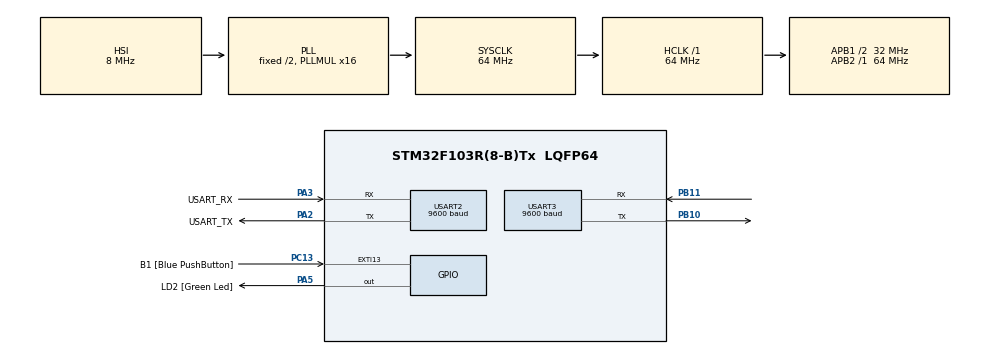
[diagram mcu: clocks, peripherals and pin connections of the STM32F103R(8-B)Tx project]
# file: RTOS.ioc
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Mcu.Family=STM32F1
PC15-OSC32_OUT.Mode=LSE-External-Oscillator
PA2.GPIO_PuPd=GPIO_NOPULL
FREERTOS.Queues01=myQueue01,16,uint16_t,0,Dynamic,NULL,NULL
FREERTOS.Tasks01=defaultTask,24,128,StartDefaultTask,Default,NULL,Dynamic,NULL,NULL;myTask02,24,128,StartTask02,Default,NULL,Dynamic,NULL,NULL;myTask03,24,128,StartTask03,Default,NULL,Dynamic,NULL,NULL
FREERTOS.BinarySemaphores01=myBinarySem01,Dynamic,NULL
PD1-OSC_OUT.Mode=HSE-External-Clock-Source
PB10.Mode=Asynchronous
PA14.GPIO_Label=TCK
PA3.GPIO_PuPd=GPIO_NOPULL
PA2.GPIO_Speed=GPIO_SPEED_FREQ_LOW
PC13-TAMPER-RTC.Signal=GPXTI13
PD0-OSC_IN.Signal=RCC_OSC_IN
FREERTOS.CountingSemaphores01=Semaphore_Cnt,5,Dynamic,NULL
RCC.APB1CLKDivider=RCC_HCLK_DIV2
PC14-OSC32_IN.Signal=RCC_OSC32_IN
PB11.Signal=USART3_RX
PA3.GPIO_Speed=GPIO_SPEED_FREQ_LOW
USART2.BaudRate=9600
RCC.SYSCLKSource=RCC_SYSCLKSOURCE_PLLCLK
ProjectManager.StackSize=0x400
VP_FREERTOS_VS_CMSIS_V2.Mode=CMSIS_V2
PD1-OSC_OUT.Signal=RCC_OSC_OUT
PA3.Mode=Asynchronous
PA13.Signal=SYS_JTMS-SWDIO
VP_SYS_VS_tim3.Mode=TIM3
USART3.BaudRate=9600
PB11.Mode=Asynchronous
ProjectManager.TargetToolchain=STM32CubeIDE
PA3.GPIO_Mode=GPIO_MODE_AF_PP
RCC.HCLKFreq_Value=64000000
RCC.APB2TimFreq_Value=64000000
RCC.USBFreq_Value=64000000
PC15-OSC32_OUT.Signal=RCC_OSC32_OUT
RCC.AHBFreq_Value=64000000
PD0-OSC_IN.Mode=HSE-External-Clock-Source
PB10.Signal=USART3_TX
NVIC.EXTI15_10_IRQn=true\:5\:0\:false\:false\:true\:true\:true\:true
PA5.Signal=GPIO_Output
PB3.Mode=Trace_Asynchronous_SW
board=NUCLEO-F103RB
RCC.RTCClockSelection=RCC_RTCCLKSOURCE_LSE
PC13-TAMPER-RTC.GPIO_Label=B1 [Blue PushButton]
RCC.PLLMUL=RCC_PLL_MUL16
NVIC.TIM3_IRQn=true\:0\:0\:false\:false\:true\:false\:false\:true
RCC.APB2Freq_Value=64000000
PC14-OSC32_IN.Mode=LSE-External-Oscillator
PA5.GPIO_ModeDefaultOutputPP=GPIO_MODE_OUTPUT_PP
PA14.Mode=Trace_Asynchronous_SW
PA5.GPIO_PuPd=GPIO_NOPULL
PA13.Mode=Trace_Asynchronous_SW
Mcu.Name=STM32F103R(8-B)Tx
PA13.GPIO_Label=TMS
PA2.Signal=USART2_TX
PB3.Signal=SYS_JTDO-TRACESWO
RCC.SYSCLKFreq_VALUE=64000000
Mcu.Package=LQFP64
NVIC.TimeBase=TIM3_IRQn
PA5.GPIO_Label=LD2 [Green Led]
USART2.VirtualMode=VM_ASYNC
USART3.VirtualMode=VM_ASYNC
PC13-TAMPER-RTC.GPIO_PuPd=GPIO_NOPULL
PA2.GPIO_Label=USART_TX
NVIC.TimeBaseIP=TIM3
PA14.Signal=SYS_JTCK-SWCLK
ProjectManager.HeapSize=0x200
FREERTOS.Timers01=myTimer01,Callback01,osTimerPeriodic,Default,NULL,Dynamic,NULL
FREERTOS.Mutexes01=Mutex1,Dynamic,NULL
PA5.GPIO_Speed=GPIO_SPEED_FREQ_LOW
NVIC.PriorityGroup=NVIC_PRIORITYGROUP_4
RCC.APB1TimFreq_Value=64000000
PA2.Mode=Asynchronous
RCC.APB1Freq_Value=32000000
PA3.GPIO_Label=USART_RX
PA3.Signal=USART2_RX
PA2.GPIO_Mode=GPIO_MODE_AF_PP
PB3.GPIO_Label=SWO

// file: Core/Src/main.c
/* USER CODE BEGIN Header */
/**
  ******************************************************************************
  * @file           : main.c
  * @brief          : Main program body
  ******************************************************************************
  * @attention
  *
  * <h2><center>&copy; Copyright (c) 2021 STMicroelectronics.
  * All rights reserved.</center></h2>
  *
  * This software component is licensed by ST under BSD 3-Clause license,
  * the "License"; You may not use this file except in compliance with the
  * License. You may obtain a copy of the License at:
  *                        opensource.org/licenses/BSD-3-Clause
  *
  ******************************************************************************
  */
/* USER CODE END Header */
#include "main.h"
#include "cmsis_os.h"
#include "usart.h"
#include "gpio.h"

/* USER CODE BEGIN Includes */
#include <stdio.h>
/* USER CODE END Includes */

void SystemClock_Config(void);
void MX_FREERTOS_Init(void);

int main(void)
{

  /* MCU Configuration--------------------------------------------------------*/

  /* Reset of all peripherals, Initializes the Flash interface and the Systick. */
  HAL_Init();

  /* Configure the system clock */
  SystemClock_Config();

  /* Initialize all configured peripherals */
  MX_GPIO_Init();
  MX_USART2_UART_Init();
  MX_USART3_UART_Init();
  /* USER CODE BEGIN 2 */
  //printf("RTOS CMSIS V2 Test\r\n");
  /* USER CODE END 2 */

  /* Init scheduler */
  osKernelInitialize();  /* Call init function for freertos objects (in freertos.c) */
  MX_FREERTOS_Init();
  /* Start scheduler */
  osKernelStart();

  /* We should never get here as control is now taken by the scheduler */
  /* Infinite loop */
  while (1)
  {

  }
}

void SystemClock_Config(void)
{
  RCC_OscInitTypeDef RCC_OscInitStruct = {0};
  RCC_ClkInitTypeDef RCC_ClkInitStruct = {0};

  /** Initializes the RCC Oscillators according to the specified parameters
  * in the RCC_OscInitTypeDef structure.
  */
  RCC_OscInitStruct.OscillatorType = RCC_OSCILLATORTYPE_HSI;
  RCC_OscInitStruct.HSIState = RCC_HSI_ON;
  RCC_OscInitStruct.HSICalibrationValue = RCC_HSICALIBRATION_DEFAULT;
  RCC_OscInitStruct.PLL.PLLState = RCC_PLL_ON;
  RCC_OscInitStruct.PLL.PLLSource = RCC_PLLSOURCE_HSI_DIV2;
  RCC_OscInitStruct.PLL.PLLMUL = RCC_PLL_MUL16;
  if (HAL_RCC_OscConfig(&RCC_OscInitStruct) != HAL_OK)
  {
    Error_Handler();
  }
  /** Initializes the CPU, AHB and APB buses clocks
  */
  RCC_ClkInitStruct.ClockType = RCC_CLOCKTYPE_HCLK|RCC_CLOCKTYPE_SYSCLK
                              |RCC_CLOCKTYPE_PCLK1|RCC_CLOCKTYPE_PCLK2;
  RCC_ClkInitStruct.SYSCLKSource = RCC_SYSCLKSOURCE_PLLCLK;
  RCC_ClkInitStruct.AHBCLKDivider = RCC_SYSCLK_DIV1;
  RCC_ClkInitStruct.APB1CLKDivider = RCC_HCLK_DIV2;
  RCC_ClkInitStruct.APB2CLKDivider = RCC_HCLK_DIV1;

  if (HAL_RCC_ClockConfig(&RCC_ClkInitStruct, FLASH_LATENCY_2) != HAL_OK)
  {
    Error_Handler();
  }
}

 /**
  * @brief  Period elapsed callback in non blocking mode
  * @note   This function is called  when TIM3 interrupt took place, inside
  * HAL_TIM_IRQHandler(). It makes a direct call to HAL_IncTick() to increment
  * a global variable "uwTick" used as application time base.
  * @param  htim : TIM handle
  * @retval None
  */
void HAL_TIM_PeriodElapsedCallback(TIM_HandleTypeDef *htim)
{
  if (htim->Instance == TIM3) {
    HAL_IncTick();
  }
}

void Error_Handler(void)
{
  __disable_irq();
  while (1)
  {
  }
}

/************************ (C) COPYRIGHT STMicroelectronics *****END OF FILE****/

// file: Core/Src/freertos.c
/* USER CODE BEGIN Header */
/**
  ******************************************************************************
  * File Name          : freertos.c
  * Description        : Code for freertos applications
  ******************************************************************************
  * @attention
  *
  * <h2><center>&copy; Copyright (c) 2021 STMicroelectronics.
  * All rights reserved.</center></h2>
  *
  * This software component is licensed by ST under Ultimate Liberty license
  * SLA0044, the "License"; You may not use this file except in compliance with
  * the License. You may obtain a copy of the License at:
  *                             www.st.com/SLA0044
  *
  ******************************************************************************
  */
/* USER CODE END Header */

#include "FreeRTOS.h"
#include "task.h"
#include "main.h"
#include "cmsis_os.h"

/* USER CODE BEGIN Includes */
#include <stdio.h>
/* USER CODE END Includes */

/* Definitions for defaultTask */
osThreadId_t defaultTaskHandle;
const osThreadAttr_t defaultTask_attributes = {
  .name = "defaultTask",
  .stack_size = 128 * 4,
  .priority = (osPriority_t) osPriorityNormal,
};
/* Definitions for myTask02 */
osThreadId_t myTask02Handle;
const osThreadAttr_t myTask02_attributes = {
  .name = "myTask02",
  .stack_size = 128 * 4,
  .priority = (osPriority_t) osPriorityNormal,
};
/* Definitions for myTask03 */
osThreadId_t myTask03Handle;
const osThreadAttr_t myTask03_attributes = {
  .name = "myTask03",
  .stack_size = 128 * 4,
  .priority = (osPriority_t) osPriorityNormal,
};
/* Definitions for myQueue01 */
osMessageQueueId_t myQueue01Handle;
const osMessageQueueAttr_t myQueue01_attributes = {
  .name = "myQueue01"
};
/* Definitions for myTimer01 */
osTimerId_t myTimer01Handle;
const osTimerAttr_t myTimer01_attributes = {
  .name = "myTimer01"
};
/* Definitions for Mutex1 */
osMutexId_t Mutex1Handle;
const osMutexAttr_t Mutex1_attributes = {
  .name = "Mutex1"
};
/* Definitions for myBinarySem01 */
osSemaphoreId_t myBinarySem01Handle;
const osSemaphoreAttr_t myBinarySem01_attributes = {
  .name = "myBinarySem01"
};
/* Definitions for Semaphore_Cnt */
osSemaphoreId_t Semaphore_CntHandle;
const osSemaphoreAttr_t Semaphore_Cnt_attributes = {
  .name = "Semaphore_Cnt"
};

/* USER CODE BEGIN FunctionPrototypes */
void Task_Action(char message);
/* USER CODE END FunctionPrototypes */

void StartDefaultTask(void *argument);
void StartTask02(void *argument);
void StartTask03(void *argument);
void Callback01(void *argument);

void MX_FREERTOS_Init(void); /* (MISRA C 2004 rule 8.1) */

void MX_FREERTOS_Init(void) {
  /* Create the mutex(es) */
  /* creation of Mutex1 */
  Mutex1Handle = osMutexNew(&Mutex1_attributes);

  /* Create the semaphores(s) */
  /* creation of myBinarySem01 */
  myBinarySem01Handle = osSemaphoreNew(1, 1, &myBinarySem01_attributes);

  /* creation of Semaphore_Cnt */
  Semaphore_CntHandle = osSemaphoreNew(5, 5, &Semaphore_Cnt_attributes);

  /* Create the timer(s) */
  /* creation of myTimer01 */
  myTimer01Handle = osTimerNew(Callback01, osTimerPeriodic, NULL, &myTimer01_attributes);

  /* Create the queue(s) */
  /* creation of myQueue01 */
  myQueue01Handle = osMessageQueueNew (16, sizeof(uint16_t), &myQueue01_attributes);

  /* Create the thread(s) */
  /* creation of defaultTask */
  defaultTaskHandle = osThreadNew(StartDefaultTask, NULL, &defaultTask_attributes);

  /* creation of myTask02 */
  myTask02Handle = osThreadNew(StartTask02, NULL, &myTask02_attributes);

  /* creation of myTask03 */
  myTask03Handle = osThreadNew(StartTask03, NULL, &myTask03_attributes);

}

void StartDefaultTask(void *argument)
{
  /* USER CODE BEGIN StartDefaultTask */
//  osThreadFlagsSet(defaultTaskHandle, 0x01);

  /* Infinite loop */
  for(;;)
  {
//	osThreadFlagsWait(0x01, osFlagsWaitAny, osWaitForever);
	printf("Task 1\r\n");
	//HAL_GPIO_TogglePin(LD2_GPIO_Port, LD2_Pin);

//	Task_Action('1');

//	osThreadFlagsSet(myTask02Handle, 0x02);
    osDelay(100);
  }
  /* USER CODE END StartDefaultTask */
}

void StartTask02(void *argument)
{
  /* USER CODE BEGIN StartTask02 */
  /* Infinite loop */
  for(;;)
  {
//	osThreadFlagsWait(0x02, osFlagsWaitAny, osWaitForever);
	printf("Task 22\r\n");
    osDelay(100);
//    osThreadFlagsSet(myTask03Handle, 0x03);
  }
  /* USER CODE END StartTask02 */
}

void StartTask03(void *argument)
{
  /* USER CODE BEGIN StartTask03 */
  /* Infinite loop */
  for(;;)
  {
//	if(osSemaphoreAcquire(myBinarySem01Handle, 0) == osOK)
//	{
//		printf("Task 333\r\n");
//	}
//	osThreadFlagsWait(0x03, osFlagsWaitAny, osWaitForever);
	printf("Task 333\r\n");
	osDelay(100);
//	printf("\r\n");
//	osThreadFlagsSet(defaultTaskHandle, 0x01);
  }
  /* USER CODE END StartTask03 */
}

/* Callback01 function */
void Callback01(void *argument)
{
}

/* USER CODE BEGIN Application */
void Task_Action(char message)
{
	ITM_SendChar(message);
	ITM_SendChar('\n');
}
/* USER CODE END Application */

/************************ (C) COPYRIGHT STMicroelectronics *****END OF FILE****/
